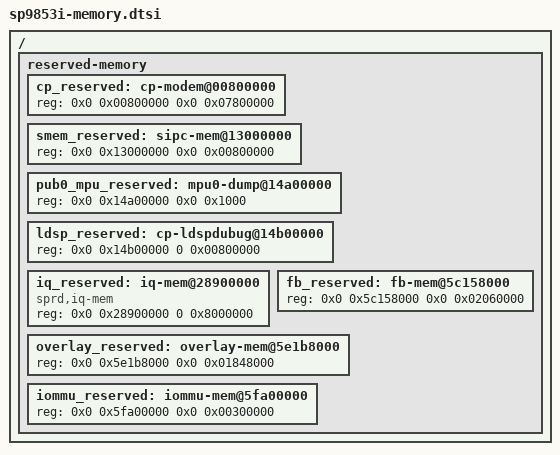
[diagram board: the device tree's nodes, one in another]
/*
 * Spreadtrum SP9861e board common memory DTS file
 *
 * Copyright (C) 2016, Spreadtrum Communications Inc.
 *
 * This file is licensed under a dual GPLv2 or X11 license.
 */
/ {
	reserved-memory {
		#address-cells = <2>;
		#size-cells = <2>;
		ranges;

		cp_reserved: cp-modem@00800000{
			reg = <0x0 0x00800000 0x0 0x07800000>;
		};

		smem_reserved: sipc-mem@13000000{
			reg = <0x0 0x13000000 0x0 0x00800000>;
		};

		pub0_mpu_reserved: mpu0-dump@14a00000 {
			reg = <0x0 0x14a00000 0x0 0x1000>;
		};

		ldsp_reserved: cp-ldspdubug@14b00000 {
			reg = <0x0 0x14b00000 0 0x00800000>;
		};

		/* used for iq capture, will be removed in normal mode */
		iq_reserved: iq-mem@28900000 {
			 compatible = "sprd,iq-mem";
			 reg = <0x0 0x28900000 0 0x8000000>;
		};
		/* if changed ,uboot dts also need change */
		fb_reserved: fb-mem@5c158000{
			reg = <0x0 0x5c158000 0x0 0x02060000>;
		};

		overlay_reserved: overlay-mem@5e1b8000{
			reg = <0x0 0x5e1b8000 0x0 0x01848000>;
		};

		iommu_reserved: iommu-mem@5fa00000{
			reg = <0x0 0x5fa00000 0x0 0x00300000>;
		};
	};
};
